# MIK32 register map
Vendor: Mikron JSC; Series: MIK32; File version: 1.0
Registers are 32-bit, read-write, reset 0x0 unless marked. A register's access mark holds for its fields unless they carry their own. Offsets are from the block's base; [hi:lo] are bit positions; {n}, {i} and the like mark numbered series.

## GPIO_IRQ — Модуль формирования прерываний
Base 0x00084C00
0x00 STATE ro — Текущее состояние линий после мультиплексоров. Номер бита соответствует линии запроса прерывания
  [7:0] STATE — Биты состояния линий после мультиплексоров
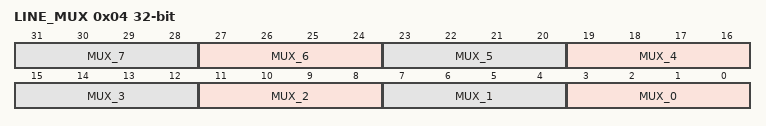
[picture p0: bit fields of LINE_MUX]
0x04 LINE_MUX wo — Управление мультиплексорами всех 8-ми линий. 4 бита кодируют выбор 1-го из 10-ти доступных портов: MUX_0 – [3:0]; MUX_1 – [7:4]; MUX_2 – [11:8]; MUX_3 – [15:12]; MUX_4 – [19:16]; MUX_5 – [23:20]; MUX_6 – [27:24]; MUX_7 – [31:28] Внимание!!! Схемотехническая ошибка в MIK32V2 ограничила чтение регистра LINE_MUX 8-ю младшими битами, а остальные читаются как «0». Запись осуществляется корректно во все 32 бита. Поэтому регистр помечен доступным только на запись. Примечание: На входы неиспользуемых линиий рекомендуется подать «заглушку» в виде логического «0» записью числа 10 в настройках мультиплексоров
  [4n+3:4n] MUX_{n} (n=4..7) — Выбор порта для линии {n}
    0=GPIO0_{n} (MUX_{n}[0] = GPIO0_{n}); 1=GPIO0_{n+8} (MUX_{n}[1] = GPIO0_{n+8}); 2=GPIO1_{n} (MUX_{n}[2] = GPIO1_{n}); 3=GPIO1_{n+8} (MUX_{n}[3] = GPIO1_{n+8}); 4=GPIO2_{n} (MUX_{n}[4] = GPIO2_{n}); 5=GPIO0_{n-4} (MUX_{n}[5] = GPIO0_{n-4}); 6=GPIO0_{n+4} (MUX_{n}[6] = GPIO0_{n+4}); 7=GPIO1_{n-4} (MUX_{n}[7] = GPIO1_{n-4}); 8=GPIO1_{n+4} (MUX_{n}[8] = GPIO1_{n+4}); 9=GPIO2_{n-4} (MUX_{n}[9] = GPIO2_{n-4}); 10=Null (MUX_{n}[10] = Null)
  [4n+3:4n] MUX_{n} (n=0..3) — Выбор порта для линии {n}
    0=GPIO0_{n} (MUX_{n}[0] = GPIO0_{n}); 1=GPIO0_{n+8} (MUX_{n}[1] = GPIO0_{n+8}); 2=GPIO1_{n} (MUX_{n}[2] = GPIO1_{n}); 3=GPIO1_{n+8} (MUX_{n}[3] = GPIO1_{n+8}); 4=GPIO2_{n} (MUX_{n}[4] = GPIO2_{n}); 5=GPIO0_{n+4} (MUX_{n}[5] = GPIO0_{n+4}); 6=GPIO0_{n+12} (MUX_{n}[6] = GPIO0_{n+12}); 7=GPIO1_{n+4} (MUX_{n}[7] = GPIO1_{n+4}); 8=GPIO1_{n+12} (MUX_{n}[8] = GPIO1_{n+12}); 9=GPIO2_{n+4} (MUX_{n}[9] = GPIO2_{n+4}); 10=Null (MUX_{n}[10] = Null)
0x08 INTERRUPT ro — Текущее состояние флагов запросов прерывания. Номер бита соответствует номеру линии
  [7:0] INTERRUPT — Биты состояния флагов запросов прерывания
0x0C ENABLE_SET — Разрешение запросов прерывания. При чтении: текущее состояние разрешений запросов. Запись «1» разрешает запрос от соответствующей линии
  [7:0] ENABLE_SET write-1-sets — Биты разрешения запросов прерывания
0x10 ENABLE_CLEAR — Запрет запросов прерывания. При чтении: текущее состояние разрешений запросов. Запись «1» запрещает запрос от соответствующей линии
  [7:0] ENABLE_CLEAR write-1-clears — Биты запрета запросов прерывания
0x14 EDGE — Выбор типа запросов прерывания по событию. При чтении – текущий тип запросов: 0: по уровню; 1: по событию (фронт или спад). Запись «1» – запрос формируется по событию для соответствующей линии
  [7:0] EDGE write-1-sets — Биты выбора типа запросов прерывания по событию
0x18 LEVEL reset 0xFF — Выбор типа запросов прерывания по уровню. При чтении – текущий тип запроса (инвертированный): 0: по событию (фронт или спад); 1: по уровню. Запись «1» – запрос формируется по уровню для соответствующей линии
  [7:0] LEVEL write-1-sets — Биты выбора типа запросов прерывания по уровню
0x1C LEVEL_SET — Выбор фронта и высокого уровня для запросов прерывания. При чтении: 0: по спаду или уровню логического «0»; 1: по фронту или уровню логической «1». Запись «1» – запрос формируется по фронту или уровню логической «1» для соответствующей линии
  [7:0] LEVEL_SET write-1-sets — Биты выбора фронта и высокого уровня для запросов прерывания
0x20 LEVEL_CLEAR — Выбор спада и низкого уровня для запросов прерывания. При чтении: 0: по спаду или уровню логического «0»; 1: по фронту или уровню логической «1». Запись «1» – запрос формируется по спаду или уровню логического «0» для соответствующей линии
  [7:0] LEVEL_CLEAR write-1-clears — Биты выбора спада и низкого уровня для запросов прерывания
0x24 ANY_EDGE_SET — Выбор запросов прерывания по любому событию. Запись «1» – запрос формируется по любому изменению соответствующей линии
  [7:0] ANY_EDGE_SET write-1-sets — Биты выбора запросов прерывания по любому событию
0x28 ANY_EDGE_CLEAR — Отмена выбора запросов прерывания по любому событию. Запись «1» – запрос не формируется по любому изменению соответствующей линии
  [7:0] ANY_EDGE_CLEAR write-1-clears — Биты отмены запросов прерывания по любому событию
0x2C CLEAR wo — Сброс флагов запросов прерывания по событию. Запись «1» – очищает флаг запроса прерывания для соответствующей линии
  [7:0] CLEAR write-1-clears — Биты сброса флагов запросов прерывания по событию
